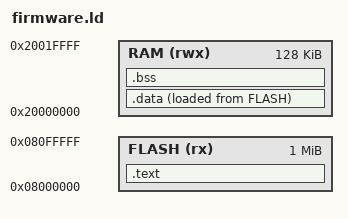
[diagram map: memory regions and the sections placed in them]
MEMORY
{
    FLASH (rx) : ORIGIN = 0x08000000, LENGTH = 1M
    RAM (rwx)  : ORIGIN = 0x20000000, LENGTH = 128K
}

SECTIONS
{
    .text :
    {
        KEEP(*(.isr_vector))
        *(.text*)
        *(.rodata*)
        . = ALIGN(4);
        _etext = .;
    } > FLASH

    .data :
    {
        _sdata = .;
        *(.data*)
        . = ALIGN(4);
        _edata = .;
    } > RAM AT > FLASH

    .bss :
    {
        _sbss = .;
        *(.bss*)
        *(COMMON)
        . = ALIGN(4);
        _ebss = .;
    } > RAM

    . = ALIGN(4);
    end = .;
}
